# MK20D5 register map
Vendor: Freescale Semiconductor, Inc.; Series: Kinetis_K; File version: 1.6
CPU: CM4 r0p1, little endian, no MPU, no FPU, VTOR, 4 interrupt priority bits
Registers are 32-bit, read-write, reset 0x0 unless marked. A register's access mark holds for its fields unless they carry their own. Offsets are from the block's base; [hi:lo] are bit positions; {n}, {i} and the like mark numbered series; 'fields as' and 'values as' point back to an identical list.

## FMC — Flash Memory Controller
Base 0x4001F000; register names take the prefix FMC_
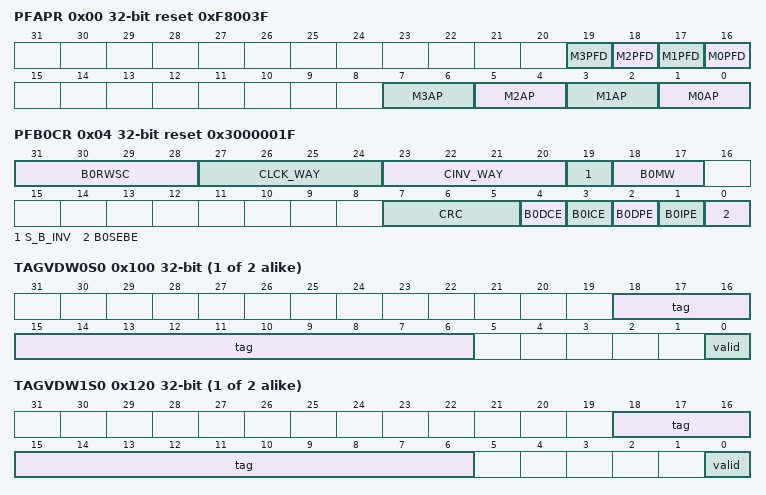
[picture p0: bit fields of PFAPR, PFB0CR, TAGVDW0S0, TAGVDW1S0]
0x00 PFAPR reset 0xF8003F — Flash Access Protection Register
  [n+16] M{n}PFD (n=0..3) — Master {n} Prefetch Disable
    0=Prefetching for this master is enabled; 1=Prefetching for this master is disabled
  [2n+1:2n] M{n}AP (n=0..3) — Master {n} Access Protection
    0=No access may be performed by this master; 1=Only read accesses may be performed by this master; 2=Only write accesses may be performed by this master; 3=Both read and write accesses may be performed by this master
0x04 PFB0CR reset 0x3000001F — Flash Control Register
  [31:28] B0RWSC ro — Read Wait State Control
  [27:24] CLCK_WAY — Cache Lock Way x
    0=Cache way is unlocked and may be displaced; 1=Cache way is locked and its contents are not displaced
  [23:20] CINV_WAY wo — Cache Invalidate Way x
    0=No cache way invalidation for the corresponding cache; 1=Invalidate cache way for the corresponding cache: clear the tag, data, and vld bits of ways selected
  [19] S_B_INV wo — Invalidate Prefetch Speculation Buffer
    0=Speculation buffer and single entry buffer are not affected; 1=Invalidate (clear) speculation buffer and single entry buffer
  [18:17] B0MW ro — Memory Width
    0=32 bits; 1=64 bits
  [7:5] CRC — Cache Replacement Control
    0=LRU replacement algorithm per set across all four ways; 2=Independent LRU with ways [0-1] for ifetches, [2-3] for data; 3=Independent LRU with ways [0-2] for ifetches, [3] for data
  [4] B0DCE — Data Cache Enable
    0=Do not cache data references; 1=Cache data references
  [3] B0ICE — Instruction Cache Enable
    0=Do not cache instruction fetches; 1=Cache instruction fetches
  [2] B0DPE — Data Prefetch Enable
    0=Do not prefetch in response to data references; 1=Enable prefetches in response to data references
  [1] B0IPE — Instruction Prefetch Enable
    0=Do not prefetch in response to instruction fetches; 1=Enable prefetches in response to instruction fetches
  [0] B0SEBE — Single Entry Buffer Enable
    0=Single entry buffer is disabled; 1=Single entry buffer is enabled
{0x100+4i} TAGVDW0S{i} (i=0..1) — Cache Tag Storage
  [18:6] tag — 13-bit tag for cache entry
  [0] valid — 1-bit valid for cache entry
{0x120+4i} TAGVDW1S{i} (i=0..1) — Cache Tag Storage
  fields as TAGVDW0S0
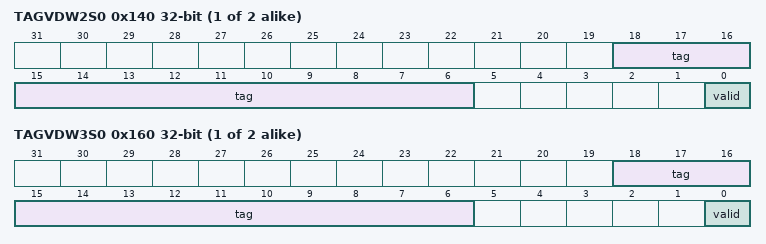
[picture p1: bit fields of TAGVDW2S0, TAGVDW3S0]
{0x140+4i} TAGVDW2S{i} (i=0..1) — Cache Tag Storage
  fields as TAGVDW0S0
{0x160+4i} TAGVDW3S{i} (i=0..1) — Cache Tag Storage
  fields as TAGVDW0S0
{0x204+8i} DATAW0S{i} (i=0..1) — Cache Data Storage
  [31:0] data — Bits [31:0] of data entry
{0x244+8i} DATAW1S{i} (i=0..1) — Cache Data Storage
  [31:0] data — Bits [31:0] of data entry
{0x284+8i} DATAW2S{i} (i=0..1) — Cache Data Storage
  [31:0] data — Bits [31:0] of data entry
{0x2C4+8i} DATAW3S{i} (i=0..1) — Cache Data Storage
  [31:0] data — Bits [31:0] of data entry

## DMAMUX0 — DMA channel multiplexor
Base 0x40021000; register names take the prefix DMAMUX0_
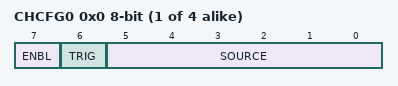
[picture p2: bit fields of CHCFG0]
{0x0+i} CHCFG{i} (i=0..3) 8-bit — Channel Configuration Register
  [7] ENBL — DMA Channel Enable
    0=DMA channel is disabled. This mode is primarily used during configuration of the DMA Mux. The DMA has separate channel enables/disables, which should be used to disable or re-configure a DMA channel.; 1=DMA channel is enabled
  [6] TRIG — DMA Channel Trigger Enable
    0=Triggering is disabled. If triggering is disabled, and the ENBL bit is set, the DMA Channel will simply route the specified source to the DMA channel. (normal mode); 1=Triggering is enabled. If triggering is enabled, and the ENBL bit is set, the DMAMUX is in periodic trigger mode.
  [5:0] SOURCE — DMA Channel Source (slot)
    0=Software_DMA_Request; 2=UART0_Receive_DMA_Request; 3=UART0_Transmit_DMA_Request; 4=UART1_Receive_DMA_Request; 5=UART1_Transmit_DMA_Request; 6=UART2_Receive_DMA_Request; 7=UART2_Transmit_DMA_Request; 14=I2S0_Receive_DMA_Request; 15=I2S0_Transmit_DMA_Request; 16=SPI0_Receive_DMA_Request; 17=SPI0_Transmit_DMA_Request; 22=I2C0_DMA_Request; {v}=FTM0_C{v-24}_DMA_Request (v=24..31); 32=FTM1_C0_DMA_Request; 33=FTM1_C1_DMA_Request; 40=ADC0_DMA_Request; 42=CMP0_DMA_Request; 43=CMP1_DMA_Request; 47=CMT_DMA_Request; 48=PDB_DMA_Request; 49=GPIO_Port_A_DMA_Request; 50=GPIO_Port_B_DMA_Request; 51=GPIO_Port_C_DMA_Request; 52=GPIO_Port_D_DMA_Request; 53=GPIO_Port_E_DMA_Request; {v}=Always_Enabled_slot_{v}_DMA_Request (v=54..63)

## Notices in the file
Redistribution and use in source and binary forms, with or without modification,
are permitted provided that the following conditions are met:
o Redistributions of source code must retain the above copyright notice, this list
of conditions and the following disclaimer.
o Redistributions in binary form must reproduce the above copyright notice, this
list of conditions and the following disclaimer in the documentation and/or
other materials provided with the distribution.
o Neither the name of Freescale Semiconductor, Inc. nor the names of its
contributors may be used to endorse or promote products derived from this
software without specific prior written permission.
THIS SOFTWARE IS PROVIDED BY THE COPYRIGHT HOLDERS AND CONTRIBUTORS "AS IS" AND
ANY EXPRESS OR IMPLIED WARRANTIES, INCLUDING, BUT NOT LIMITED TO, THE IMPLIED
WARRANTIES OF MERCHANTABILITY AND FITNESS FOR A PARTICULAR PURPOSE ARE
DISCLAIMED. IN NO EVENT SHALL THE COPYRIGHT HOLDER OR CONTRIBUTORS BE LIABLE FOR
ANY DIRECT, INDIRECT, INCIDENTAL, SPECIAL, EXEMPLARY, OR CONSEQUENTIAL DAMAGES
(INCLUDING, BUT NOT LIMITED TO, PROCUREMENT OF SUBSTITUTE GOODS OR SERVICES;
LOSS OF USE, DATA, OR PROFITS; OR BUSINESS INTERRUPTION) HOWEVER CAUSED AND ON
ANY THEORY OF LIABILITY, WHETHER IN CONTRACT, STRICT LIABILITY, OR TORT
(INCLUDING NEGLIGENCE OR OTHERWISE) ARISING IN ANY WAY OUT OF THE USE OF THIS
SOFTWARE, EVEN IF ADVISED OF THE POSSIBILITY OF SUCH DAMAGE.
